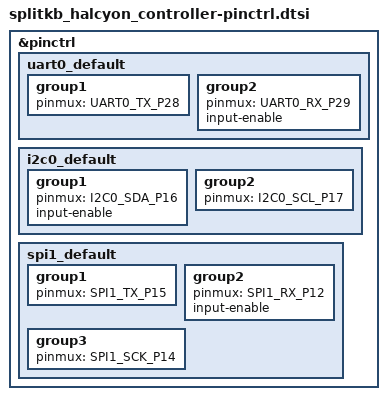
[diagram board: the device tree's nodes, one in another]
/*
 * Copyright (c) 2021, Yonatan Schachter
 * SPDX-License-Identifier: Apache-2.0
 */

#include <dt-bindings/pinctrl/rpi-pico-rp2040-pinctrl.h>

&pinctrl {
	uart0_default: uart0_default {
		group1 {
			pinmux = <UART0_TX_P28>;
		};
		group2 {
			pinmux = <UART0_RX_P29>;
			input-enable;
		};
	};

	i2c0_default: i2c0_default {
		group1 {
			pinmux = <I2C0_SDA_P16>;
			input-enable;
		};
		group2 {
			pinmux = <I2C0_SCL_P17>;
		};
	};

	spi1_default: spi1_default {
		group1 {
			pinmux = <SPI1_TX_P15>;
		};
		group2 {
			pinmux = <SPI1_RX_P12>;
			input-enable;
		};
		group3 {
			pinmux = <SPI1_SCK_P14>;
		};
	};
};
